# TC37XPD register map
Vendor: Infineon; Series: ATVMC; File version: 100
CPU: other r0p0, little endian, MPU, FPU, vendor SysTick, 4 interrupt priority bits
Registers are 32-bit, read-write, reset 0x0 unless marked. A register's access mark holds for its fields unless they carry their own. Offsets are from the block's base; [hi:lo] are bit positions; {n}, {i} and the like mark numbered series; 'fields as' and 'values as' point back to an identical list.

## SCU (part 2 of 3) — System Control Unit
Base 0xF0036000
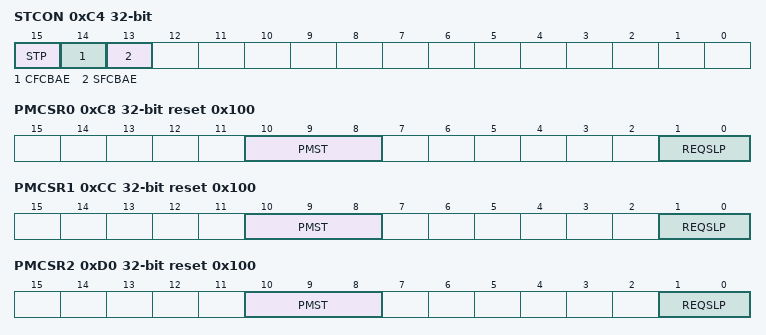
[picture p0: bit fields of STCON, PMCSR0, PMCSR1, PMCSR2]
0xC4 STCON access per field — Start up Configuration Register resetvalue={Application Reset:0x0}
  [15] STP rw — Start up Protection Setting STP. This bit will be always set by FW and can t be reset. This bit is also cleared by an Application Reset. STP is automatically set when a shutdown trap occurs. The start up protection for the system generated out of this bit can be overruled deactivated if bit RTID.RT14 is set AND signal tcu nostp request from the TCU is asserted.
  [14] CFCBAE wo — Clear Flash Config. Sector Access Enable CFCBAE. Setting this bit clears bit STSTAT.FCBAE. Reading this bit returns always a zero.
  [13] SFCBAE wo — Set Flash Config. Sector Access Enable SFCBAE. Setting this bit sets bit STSTAT.FCBAE. Reading this bit returns always a zero. If bits SFCBAE and CFCBAE are both set during the same access then bit STSTAT.FCBAE is set.
0xC8 PMCSR0 access per field reset 0x100 — Power Management Control and Status Register resetvalue={Application Reset:0x100}
  [10:8] PMST ro — Power management Status PMST. This bit field reflects the current status of the CPU.
  [1:0] REQSLP rw — Idle Mode and Sleep Mode Request REQSLP. In Idle Mode or Sleep Mode these bits are cleared in response to an interrupt for the CPU or when bit 15 of the corresponding CPU Watchdog Timer register bit WDTCPUxSR.TIM 15 changes from 0 to 1. In Standby Mode these bits are cleared on wake up. REQSLP maybe written only when either CPU or Safety ENDINIT bits are set to 0. CPU ENDINIT bit has to be set back after REQSLP is written for the mode transition to take place. In case of Safety ENDINIT the mode transition will be issued immediately and does not wait till Safety ENDINIT is set back to 1 again. No explicit acknowledge to SCU on System Standby request. System Standby entry in a few cycles.
0xCC PMCSR1 access per field reset 0x100 — Power Management Control and Status Register resetvalue={Application Reset:0x100}
  fields as PMCSR0
0xD0 PMCSR2 access per field reset 0x100 — Power Management Control and Status Register resetvalue={Application Reset:0x100}
  fields as PMCSR0
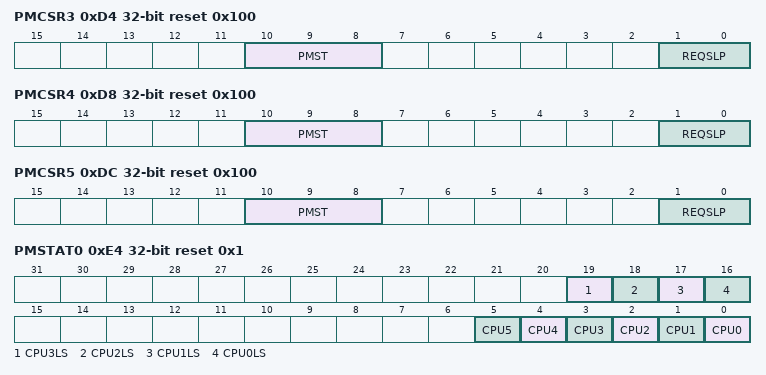
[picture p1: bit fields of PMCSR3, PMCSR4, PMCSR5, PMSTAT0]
0xD4 PMCSR3 access per field reset 0x100 — Power Management Control and Status Register resetvalue={Application Reset:0x100}
  fields as PMCSR0
0xD8 PMCSR4 access per field reset 0x100 — Power Management Control and Status Register resetvalue={Application Reset:0x100}
  fields as PMCSR0
0xDC PMCSR5 access per field reset 0x100 — Power Management Control and Status Register resetvalue={Application Reset:0x100}
  fields as PMCSR0
0xE4 PMSTAT0 ro reset 0x1 — Power Management Status Register 0 resetvalue={Application Reset:0x1}
  [19] CPU3LS — CPU3LS Status CPU3LS. This bit field reflects the current status of CPU3 Lockstep Checker Core.The activation of the Lockstep is configured in UCB BMI configuration and determines the default status. The default reset value 0 is for the case where CPU0LS is disabled in UCB BMI configuration.
  [18] CPU2LS — CPU2LS Status CPU2LS. This bit field reflects the current status of CPU2 Lockstep Checker Core.The activation of the Lockstep is configured in UCB BMI configuration and determines the default status. The default reset value 0 is for the case where CPU0LS is disabled in UCB BMI configuration.
  [17] CPU1LS — CPU1LS Status CPU1LS. This bit field reflects the current status of CPU1 Lockstep Checker Core.The activation of the Lockstep is configured in UCB BMI configuration and determines the default status. The default reset value 0 is for the case where CPU0LS is disabled in UCB BMI configuration.
  [16] CPU0LS — CPU0LS Status CPU0LS. This bit field reflects the current status of CPU0 Lockstep Checker Core.The activation of the Lockstep is configured in UCB BMI configuration and determines the default reset value. The default reset value 0 is for the case where CPU0LS is disabled in UCB BMI configuration.
  [n] CPU{n} (n=0..5) — CPU{n} Status CPU{n}. This bit field reflects the current status of CPU{n}.
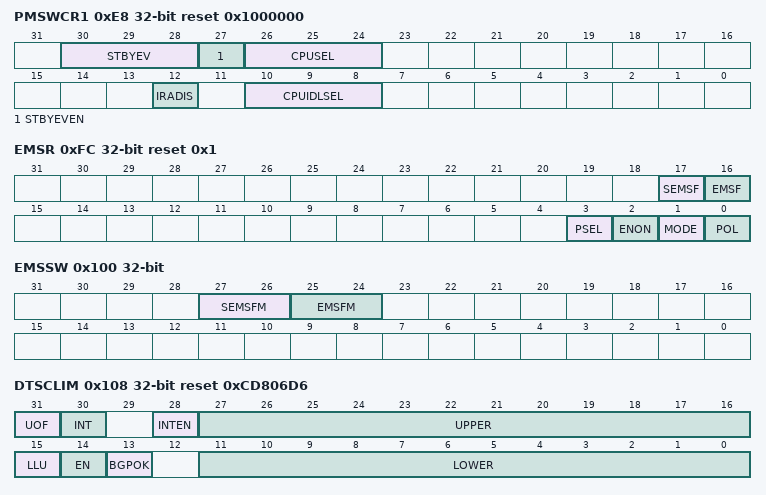
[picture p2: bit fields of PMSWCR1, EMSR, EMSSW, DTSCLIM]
0xE8 PMSWCR1 access per field reset 0x1000000 — Standby and Wake up Control Register 1 resetvalue={Cold PowerOn Reset:0x1000000}
  [30:28] STBYEV rw — Standby Entry Event Configuration STBYEV. All other bit combinations are reserved.
  [27] STBYEVEN wo — Standby Entry Event configuration enable STBYEVEN
  [26:24] CPUSEL rw — CPU selection for Sleep and Standby mode CPUSEL. All other CPUSEL bit combinations are reserved.
  [12] IRADIS rw — Idle Request Acknowledge Sequence Disable IRADIS. This bit enables SCU Idle Request Acknowledge sequence to all modules on Standby entry. IRADIS bit has no effect incase of Standby entry triggered via PWRWKEN register bit. This bit shall be set before Standby entry to disable Idle request acknowledge sequence so that standby request is not blocked by a pending reset idle request acknowledge sequence.
  [10:8] CPUIDLSEL rw — CPU selection for Idle mode CPUIDLSEL. This bit field allows a CPUx to issue Idle request to other CPUs in addition to itself. A request for Idle via PMCSRx.REQSLP 01 by CPUx will also trigger Idle requests to all other CPUs. All other CPUIDLSEL bit combinations are reserved.
0xFC EMSR access per field reset 0x1 — Emergency Stop Register resetvalue={Application Reset:0x1}
  [17] SEMSF ro — SMU Emergency Stop Flag SEMSF. This bit indicates that an SMU Safety Alarm triggered emergency stop condition has occurred.
  [16] EMSF ro — Emergency Stop Flag EMSF. This bit indicates that a synchronous mode port triggered emergency stop condition has occurred.
  [3] PSEL rw — PORT Select PSEL. This bit selects which one of the two Emergency Stop port options is monitored.
  [2] ENON rw — Enable ON ENON. This bit enables the setting of flag EMSF by an inactive to active level transition of input signal.
  [1] MODE rw — Mode Selection MODE. This bit determines the operating mode of the emergency stop signal.
  [0] POL rw — Input Polarity POL. This bit determines the polarity of the configured Emergency Stop input.
0x100 EMSSW wo — Emergency Stop Software set and clear register resetvalue={Application Reset:0x0}
  [27:26] SEMSFM — SMU Emergency Stop Flag Modification SEMSFM. This bit field sets or clears flag SEMSF via software. In case of a simultaneous hardware and software modification request the hardware operation will be executed. SEMSFM is always read as 00 B .
  [25:24] EMSFM — Emergency Stop Flag Modification EMSFM. This bit field sets or clears flag EMSF via software. In case of a simultaneous hardware and software modification request the hardware operation will be executed. EMSFM is always read as 00 B .
0x104 DTSCSTAT ro — Core Die Temperature Sensor Status Register resetvalue={Application Reset:0x0}
  [11:0] RESULT — Result of the DTSC Measurement RESULT. This bit field shows the result of the DTSC measurement. The value given is directly related to the die temperature and can be evaluated using the following formula. T 176 C RESULT Gnom 273.15 T 176 K RESULT G nom RESULT G nom T 176 C 273.15 G nom T 176 K G nom 7.505
0x108 DTSCLIM access per field reset 0xCD806D6 — Core Die Temperature Sensor Limit Register resetvalue={Application Reset:0x0CD806D6}
  [31] UOF rw — DTSC Upper Limit Overflow UOF. When this bit is set the related SMU DTSC alarm trigger is generated. This bit has to be written with zero in order to clear it. Writing a one has no effect. This bit is set when a DTSC measurement is finished and the result is exceeding the upper limit i.e. DTSCLIM.UPPER .
  [30] INT rw — DTSC Interrupt status flag. This bit is set when SMU DTSC interrupt is generated when a DTSC measurement is finished. This bit is cleared by writing a zero. Writing a one has no effect.
  [28] INTEN rw — DTSC Interrupt Enable. This bitfield enables the Core Die Temperature Sensor DTSC interrupt. The bitfield is reset on an application reset.
  [27:16] UPPER rw — DTSC Upper Limit UPPER. This bit field defines the upper limit of the DTSC temperature check. The DTSC measurement result is compared against this value and if the measurement result is greater than or equal to the configured UPPER bitfield value flag UOF is set.
  [15] LLU rw — DTSC Lower Limit Underflow LLU. When this bit is set the related SMU DTSC alarm trigger is generated. This bit has to be written with zero in order to clear it. Writing a one has no effect. This bit is set when a DTSC measurement is finished and the result is below the lower limit i.e. DTSCLIM.LOWER .
  [14] EN rw — DTSC Enable. This bitfield enables the Core Die Temperature Sensor DTSC . The bitfield is reset on an application reset.
  [13] BGPOK ro — DTSC Bandgap OK. This bitfield indicates that the bandgap reference for the Core Die Temperature Sensor DTSC is available and ok.
  [11:0] LOWER rw — DTSC Lower Limit LOWER. This bit field defines the lower limit of the DTSC temperature check. The DTSC measurement result is compared against this value and if the measurement result is less than or equal to the configured LOWER bitfield value flag LLU is set.
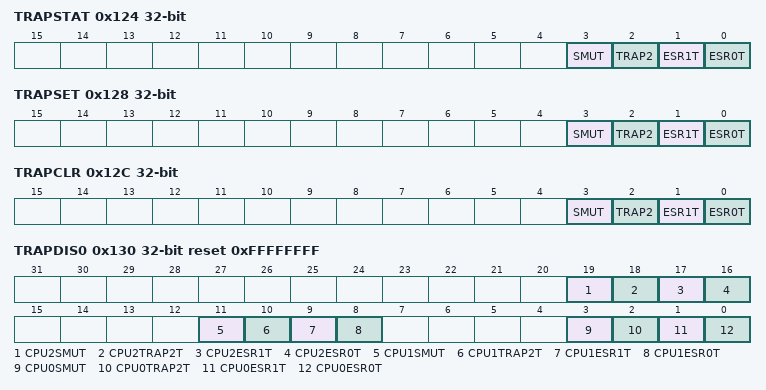
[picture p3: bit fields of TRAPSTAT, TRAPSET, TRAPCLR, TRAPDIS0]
0x124 TRAPSTAT ro (reset mask 0xFFFFFFF0) — Trap Status Register resetvalue={System Reset:0x0}
  [3] SMUT — SMU Alarm Trap Request Flag SMUT. This bit is set if an SMU Alarm is indicated. This bit can be cleared by setting bit TRAPCLR.SMUT. This bit can be set by setting bit TRAPSET.SMUT. Reset value of this bit is 0
  [2] TRAP2 — Trap Bit 2 Request Flag TRAP2. This bit can be cleared by setting bit TRAPCLR.TRAP2. This bit can be set by setting bit TRAPSET.TRAP2. Reset value of this bit is 0
  [1] ESR1T — ESR1 Trap Request Flag ESR1T. This bit is set if an ESR1 event is triggered. This bit can be cleared by setting bit TRAPCLR.ESR1T. This bit can be set by setting bit TRAPSET.ESR1T. Reset value of this bit is 0
  [0] ESR0T — ESR0 Trap Request Flag ESR0T. This bit is set if an ESR0 event is triggered. This bit can be cleared by setting bit TRAPCLR.ESR0T. This bit can be set by setting bit TRAPSET.ESR0T. Observed reset value after boot will depend upon ARI mode because of ESR pin transition.
0x128 TRAPSET wo — Trap Set Register resetvalue={System Reset:0x0}
  [3] SMUT — Set Trap Request Flag SMUT SMUT. Setting this bit sets bit TRAPSTAT.SMUT. Clearing this bit has no effect. Reading this bit returns always zero.
  [2] TRAP2 — Set Trap Request Flag TRAP2 TRAP2. Setting this bit sets bit TRAPSTAT.TRAP2. Clearing this bit has no effect. Reading this bit returns always zero.
  [1] ESR1T — Set Trap Request Flag ESR1T ESR1T. Setting this bit sets bit TRAPSTAT.ESR1T. Clearing this bit has no effect. Reading this bit returns always zero.
  [0] ESR0T — Set Trap Request Flag ESR0T ESR0T. Setting this bit sets bit TRAPSTAT.ESR0T. Clearing this bit has no effect. Reading this bit returns always zero.
0x12C TRAPCLR wo — Trap Clear Register resetvalue={System Reset:0x0}
  [3] SMUT — Clear Trap Request Flag SMUT SMUT. Setting this bit clears bit TRAPSTAT.SMUT. Clearing this bit has no effect. Reading this bit returns always zero.
  [2] TRAP2 — Clear Trap Request Flag TRAP2 TRAP2. Setting this bit clears bit TRAPSTAT.TRAP2. Clearing this bit has no effect. Reading this bit returns always zero.
  [1] ESR1T — Clear Trap Request Flag ESR1T ESR1T. Setting this bit clears bit TRAPSTAT.ESR1T. Clearing this bit has no effect. Reading this bit returns always zero.
  [0] ESR0T — Clear Trap Request Flag ESR0T ESR0T. Setting this bit clears bit TRAPSTAT.ESR0T. Clearing this bit has no effect. Reading this bit returns always zero.
0x130 TRAPDIS0 reset 0xFFFFFFFF — Trap Disable Register 0 resetvalue={Application Reset:0x0FFFFFFFF}
  [19] CPU2SMUT — Disable Trap Request SMUT on CPU2 If product has CPU2 CPU2SMUT
  [18] CPU2TRAP2T — Disable Trap Request TRAP2T on CPU2 If product has CPU2 CPU2TRAP2T
  [17] CPU2ESR1T — Disable Trap Request ESR1T on CPU2 If product has CPU2 CPU2ESR1T
  [16] CPU2ESR0T — Disable Trap Request ESR0T on CPU2 If product has CPU2 CPU2ESR0T
  [11] CPU1SMUT — Disable Trap Request SMUT on CPU1 If product has CPU1 CPU1SMUT
  [10] CPU1TRAP2T — Disable Trap Request TRAP2T on CPU1 If product has CPU1 CPU1TRAP2T
  [9] CPU1ESR1T — Disable Trap Request ESR1T on CPU1 If product has CPU1 CPU1ESR1T
  [8] CPU1ESR0T — Disable Trap Request ESR0T on CPU1 If product has CPU1 CPU1ESR0T
  [3] CPU0SMUT — Disable Trap Request SMUT on CPU0 CPU0SMUT
  [2] CPU0TRAP2T — Disable Trap Request TRAP2T on CPU0 CPU0TRAP2T
  [1] CPU0ESR1T — Disable Trap Request ESR1T on CPU0 CPU0ESR1T
  [0] CPU0ESR0T — Disable Trap Request ESR0T on CPU0 CPU0ESR0T
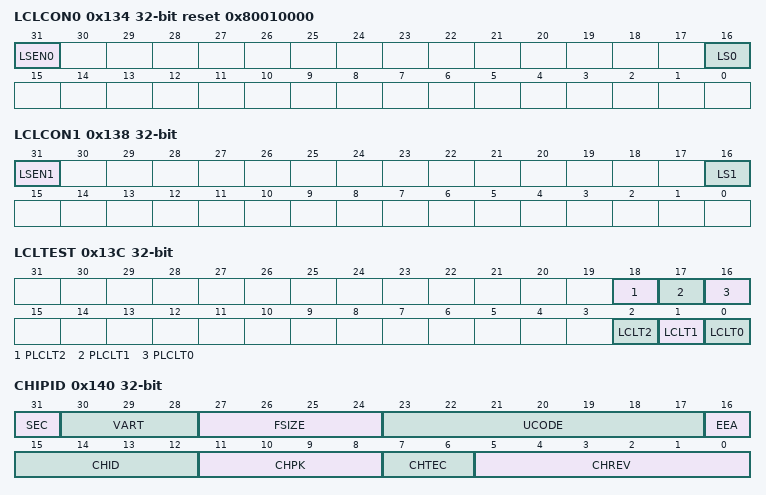
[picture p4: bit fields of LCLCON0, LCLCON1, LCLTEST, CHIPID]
0x134 LCLCON0 access per field reset 0x80010000 — LCL CPU0 and CPU2 Control Register resetvalue={Cold PowerOn Reset:0x080018001,Cold PowerOn Reset:0x080010000,Cold PowerOn Reset:0x080018001}
  [31] LSEN0 rw — Lockstep Enable LSEN0. This bit may only be written by SSW during boot. Enable lockstep CPU monitoring for the associated processor core CPU0. After cold reset lockstep is enabled by default. The LSEN bit may be cleared during the boot to disable lockstep mode. SMU lockstep fault reporting should be disabled when lockstep is disabled.
  [16] LS0 ro — Lockstep Mode Status LS0. This bit indicates whether CPU0 is currently running in lockstep monitor mode
0x138 LCLCON1 access per field (reset mask 0x7FFE7FFE) — LCL CPU1 and CPU3 Control Register resetvalue={Cold PowerOn Reset:0x080018001,Cold PowerOn Reset:0x080010000,Cold PowerOn Reset:0x0,Cold PowerOn Reset:0x080018001}
  [31] LSEN1 rw — Lockstep Enable LSEN1. This bit may only be written by SSW during boot. Enable lockstep CPU monitoring for the associated processor core CPU1. If the product has no lockstep capability for CPU1 then this enables only the PFLASH access monitoring for CPU1. After cold reset lockstep is enabled by default. The LSEN bit may be cleared during the boot to disable lockstep mode. SMU lockstep fault reporting should be disabled when lockstep is disabled.
  [16] LS1 ro — Lockstep Mode Status LS1. This bit indicates whether CPU1 is currently running in lockstep monitor mode
0x13C LCLTEST wo — LCL Test Register resetvalue={System Reset:0x0}
  [18] PLCLT2 — PFI2 Lockstep Test . Fault injection for PFI2 lockstep. Reads as zero.
  [17] PLCLT1 — PFI1 Lockstep Test . Fault injection for PFI1 lockstep. Reads as zero.
  [16] PLCLT0 — PFI0 Lockstep Test. Fault injection for PFI0 lockstep. Reads as zero.
  [2] LCLT2 — LCL2 Lockstep Test LCLT2. Fault injection for LCL2. Reads as zero.
  [1] LCLT1 — LCL1 Lockstep Test LCLT1. Fault injection for LCL1. Reads as zero.
  [0] LCLT0 — LCL0 Lockstep Test LCLT0. Fault injection for LCL0. Reads as zero.
0x140 CHIPID access per field reset not defined — Chip Identification Register resetvalue={System Reset:0x0,CFS Value:0x0}
  [31] SEC rw — Security Device Available SEC. This bit field is updated by SSW from config sector. This bit field indicates whether the product has a Hardware Security Module
  [30:28] VART rw — Variant VART. This bit field is used for variant identification. It is used to identify product variants with non standard temperature profile max frequency package pitch or customer feature sets. Note that variants do not include HSM availability Flash Size or Emulation availability options which are handled by the SEC FSIZE and EEA fields respectively. For coding details see Product Datasheet
  [27:24] FSIZE rw — Program Flash Size FSIZE. This bit field indicates available program flash size for this device. For more details see Product Datasheet.
  [23:17] UCODE rw — µCode Version UCODE. This bit field displays the Version X.Y of the flash µCode.
  [16] EEA ro — Emulation or ADAS Extension Available EEA. Indicates if the emulation or ADAS extension hardware is available or not.
  [15:12] CHID rw — Chip Product CHID. These bits indicate the base product. For further details refer to the Product Datasheet Updated by SSW from config sector.
  [11:8] CHPK rw — Chip Package CHPK. These bits indicate the package. For further details refer to the Product Datasheet Updated by SSW from config sector. Use future variant codes for downconfigured silicon
  [7:6] CHTEC ro — Chip Family CHTEC. These bits indicate the product family and are changed only with a redesign. Hard wired on top level.
  [5:0] CHREV ro — Chip Revision Number CHREV. This bit field indicates the revision number of the AurixPlus Platform device. The value of this bit field is defined in the product Data Sheet. Bits 3 0 are connected to the layer prog inputs 3 0 . Bits 3 0 are used to indicate the steps. These updates can be done with any metal fix or FW ROM change. Bits 5 4 are hard wired on top level. Bits 5 4 define the major silicon design steps A B C D ... . These bits can be changed only with a major redesign.
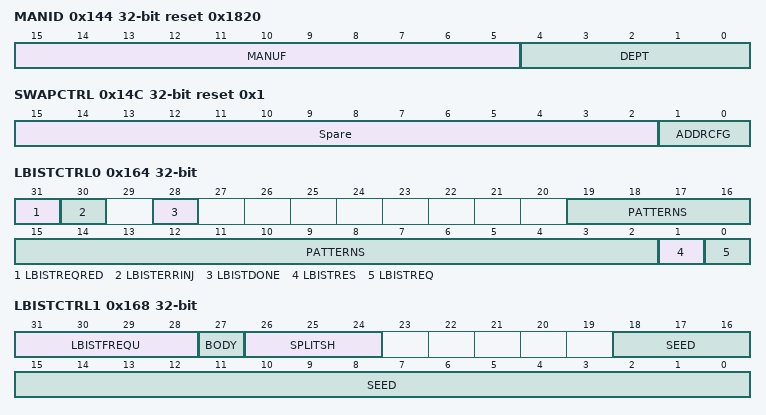
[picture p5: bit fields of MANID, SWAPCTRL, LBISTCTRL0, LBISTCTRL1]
0x144 MANID ro reset 0x1820 — Manufacturer Identification Register resetvalue={System Reset:0x1820}
  [15:5] MANUF — Manufacturer Identification Number MANUF. This is a JEDEC normalized manufacturer code. MANUF C1 H stands for Infineon Technologies.
  [4:0] DEPT — Department Identification Number DEPT. 00 H indicates the Automotive amp Industrial microcontroller department within Infineon Technologies.
0x14C SWAPCTRL reset 0x1 — Address Map Control Register resetvalue={System Reset:0x1}
  [15:2] Spare — Spare address configuration registers. Spare read write bits
  [1:0] ADDRCFG — Address Configuration. Configures the currently used address map standard alternate selection
0x164 LBISTCTRL0 access per field (reset mask 0xEFF00003) — Logic BIST Control 0 Register resetvalue={System Reset:0x0,CFS Value:0x400}
  [31] LBISTREQRED rw — LBIST Request Redundancy. This bit represents the safety double of LBISTCTRL0.LBISTREQ. In order to generate a new LBIST request both LBISTREQRED and LBISTREQ bits must be set to high due to safety reasons. The request will only be approved if LBISTCTRL0.LBISTDONE bit reflects a 0 value. If read this bit always returns a 0 .
  [30] LBISTERRINJ rw — LBIST Test Mode Alarm Error Injection. If written high this bit trigger both the LBIST and the test mode alarm. This is required to allow self testing of all LBIST and test mode related safety mechanisms in the TCU. The bit will be reset automatically once the LBIST and test mode alarm indicator signals from TCU are asserted. From these indicator signals SCU will also generate corresponding alarm trigger signals for SMU.
  [28] LBISTDONE ro — LBIST Execution Indicator LBISTDONE. This bit indicates the actual LBIST controller execution status
  [19:2] PATTERNS rw — LBIST Pattern Number PATTERNS. This field defines the number of scan patterns i.e. scan loads which will be executed during the LBIST procedure. Please note that the value programmed to this field determines the number scan capture phases not the number of scan chain load unload phases i.e. a value of 0x00001 will result in two scan chain loads with on capture in between a value of 0x00002 will result in 3 scan chain loads with 2 captures etc. . Consequently a value of 0x00000 is not valid because no capture would be executed in this case.
  [1] LBISTRES wo — LBIST Reset LBISTRES. If written high this bit synchronously brings back the LBIST controller to its initial Reset Idle state and also clears the stored MISR signature to allow another execution from CPU side. As a consequence the LBISTCTRL0 .LBISTDONE and SCU LBISTCTRL3.SIGNATURE bits will be set to x2019 0 x2019 . If read this bit always returns a x2018 0 x2019 . It is strongly recommended to not change the LBISTFREQU parameter in LBISTCTRL1 after this bit has been set to 1 because there is no guarantee that the new frequency parameter value will be transferred to the LBIST controller in time before the next LBIST run is started from user side i.e. LBISTCTRL0.LBISTREQ is set to 1 .
  [0] LBISTREQ wo — LBIST Request LBISTREQ. If written high this bit requests the execution of an automatic scan test procedure. The request will only be approved if LBISTCTRL0 .LBISTDONE bit reflects a 8217 0 8217 value i.e. no LBIST procedure was triggered since the last power on reset or LBIST controller has been restarted through the LBISTCTRL0 .LBISTRES bit . If read this bit always returns a 8216 0 8217 . This bit shall be implemented in a safety relevant way to avoid unintended activation of LBIST during application. LBIST execution time depends on the number of scan loads as defined in the PATTERNS field.
0x168 LBISTCTRL1 (reset mask 0xABFFFFF8) — Logic BIST Control 1 Register resetvalue={System Reset:0x0,CFS Value:0x54000007}
  [31:28] LBISTFREQU — LBIST Frequency Selection LBISTFREQU. Through this register field a pre scaler factor between 1..16 is selectable for LBIST operation clock derived from EVR oscillator . This will allow to determine the LBIST scan shift frequency. Value of these bits will be mirrored inside of LBIST controller and become effective if a new LBIST procedure has been successfully initiated from system side via LBISTCTRL0 .LBISTREQ . It is strongly recommended not to change the value of this field after LBISTCTRL0.LBISTRES has been set to high because there is no guarantee that the new frequency parameter value will be transferred to the LBIST controller in time before the next LBIST run is started from user side i.e. LBISTCTRL0.LBISTREQ is set to 1
  [27] BODY — Body Application Indicator BODY. The value of this bit will determine the static reset behavior of all GPIOs during LBIST execution. If set to low GPIOs will show a weak pull up behavior if set to high GPIOs are constrained to tri state. A high value must be written to this bit in case LBIST shall be executed for body applications.
  [26:24] SPLITSH — LBIST Split Shift Selection SPLITSH. The value of this bit will allow to run LBIST with partitioned scan shift operation in order to reduce the power consumption.
  [18:0] SEED — LBIST Seed SEED. This field determines which pattern is applied to the EDT channel inputs 1 19 during LBIST execution.
0x16C LBISTCTRL2 (reset mask 0xFFFFFFC2) — Logic BIST Control 2 Register resetvalue={System Reset:0x0,CFS Value:0x3D}
  [11:0] LENGTH — LBIST Maximum Scan Chain Length LENGTH. This field defines the number of shift cycles for each LBIST scan load. It will be automatically loaded with the product specific value stored in Flash config sector during startup software execution.
0x170 LBISTCTRL3 ro — Logic BIST Control 3 Register resetvalue={System Reset:0x0,CFS Value:0x0}
  [31:0] SIGNATURE — LBIST Signature SIGNATURE. This field reflects the MISR signature from the last LBIST execution. It is mirrored from LBIST controller inside TCU and only valid if LBISTCTRL0 .LBISTDONE is read with a high value. In case of a restart of the LBIST controller via LBISTCTRL0 .LBISTRES function the signature value will be synchronously reset to all 0. Please address the specific device appendix document for a description on the SIGNATURE value depending on the LBIST run configuration.
0x184 STMEM1 — Start up Memory Register 1 resetvalue={PowerOn Reset:0x0}
  [31:0] MEM — Memory MEM. This register is used by the start up software as memory.
0x188 STMEM2 — Start up Memory Register 2 resetvalue={System Reset:0x0}
  fields as STMEM1
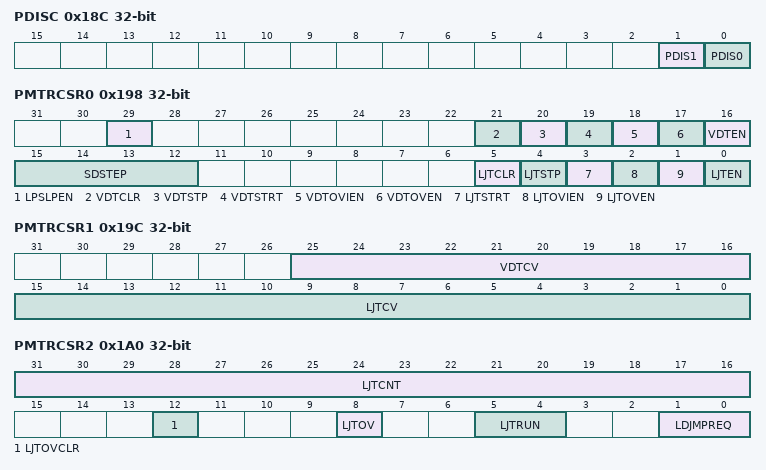
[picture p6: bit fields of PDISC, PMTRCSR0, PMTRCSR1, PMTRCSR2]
0x18C PDISC — Pad Disable Control Register resetvalue={System Reset:0x0}
  [1] PDIS1 — Pad Disable for ESR Pin 1 PDIS1. This bit disables the pad.
  [0] PDIS0 — Pad Disable for ESR Pin 1 PDIS1. This bit disables the pad.
0x198 PMTRCSR0 access per field — Power Management Transition Control and Status Register 0 resetvalue={Cold PowerOn Reset:0x0}
  [29] LPSLPEN rw — EVRC Low Power Mode activation on a Sleep Request LPSLPEN. PMS This bit field enables the activation of LPM EVRC mode on a sleep request. If this bit is set SCU sends lp enable signal on Sleep request to PMS which is OR ed with EVRSDCTRL2.EVRCMOD value and is provided to EVRC regulator. PMSLE Reserved no function no LPM for SC DCDC EVRC .
  [21] VDTCLR wo — Voltage Droop Timer Clear VDTCLR. This bit field clear Voltage Droop timer count. This is intended for test purposes. This bit resets VDT and clears VDTRUN if VDTEN bit is set.
  [20] VDTSTP rw — Voltage Droop Timer Stop VDTSTP. This bit field stops Voltage Droop timer. SCU cancels the droop request via signal sd droop cntr i 160 160 00. This is intended for test purposes. The VDTSTP remains set on a write and is to be explicitly cleared by software. The VDTSTP stops the counter at the current value and timer re starts from that value when VDTSTP is cleared and VDTSTRT is set.
  [19] VDTSTRT rw — Voltage Droop Timer Start VDTSTRT. This bit field starts Voltage Droop timer. This is intended for test purposes. The VDTSTRT remains set on a write and is cleared when VDTOV bit is set if VDTOVEN bit is enabled.
  [18] VDTOVIEN rw — Voltage Droop Timer Overflow Interrupt Enable VDTOVIEN. This bit field enables the activation of interrupt on timer overflow or time out.
  [17] VDTOVEN rw — Voltage Droop Timer Overflow Enable VDTOVEN. This bit field enables the update of VDTOV status bit on timer overflow or time out.
  [16] VDTEN rw — Voltage Droop Timer Enable VDTEN. This bit field enables the usage of Voltage Droop timer.
  [15:12] SDSTEP rw — Droop Voltage Step vdroop step i SDSTEP. This bit field defines the voltage offset for droop compensation on a load jump to the EVRC setpoint value. The request is made via SCU PMTRCSR3 .VDROOPREQ sd droop cntr i on an anticipated load jump with a voltage offset equal to the SDSTEP x 5 160 mV. The droop step is a positive offset if VDROOPREQ 160 160 01b and is a negative offset if VDROOPREQ 160 160 10b and no offset is applied if VDROOPREQ 160 160 00b. Maximum Droop 80 160 mV.
  [5] LJTCLR wo — Load Jump Timer Clear LJTCLR. This bit field clear Load jump timer count. This is intended for test purposes. This bit resets LJT and clears LJTRUN if LJTEN bit is set.
  [4] LJTSTP rw — Load Jump Timer Stop LJTSTP. This bit field stops Load jump timer. This is intended for test purposes. The LJTSTP remains set on a write and is to be explicitly cleared by software. The LJTSTP stops the counter at the current value and timer re starts from that value when LJTSTP is cleared and LJTSTRT is set.
  [3] LJTSTRT rw — Load Jump Timer Start LJTSTRT. This bit field starts Load jump timer. This is intended for test purposes. The LJTSTRT remains set on a write and is cleared when LJTOV bit is set if LJTOVEN bit is enabled.
  [2] LJTOVIEN rw — Load Jump Timer Overflow Interrupt Enable LJTOVIEN. This bit field enables the activation of interrupt on timer overflow or time out.
  [1] LJTOVEN rw — Load Jump Timer Overflow Enable LJTOVEN. This bit field enables the update of LJTOV status bit on timer overflow or time out.
  [0] LJTEN rw — Load Jump Timer Enable LJTEN. This bit field enables the usage of load jump timer.
0x19C PMTRCSR1 — Power Management Transition Control and Status Register 1 resetvalue={Cold PowerOn Reset:0x0}
  [25:16] VDTCV — Voltage Droop Timer Compare Setpoint Value VDTCV. This bit field defines the compare setpoint value of Voltage Droop timer. The compare event would lead to VDTOV bit being set and VDT interrupt being raised. The VDTRUN status bit VDROOPREQ bit and VDTCNT value is reset to 0 on a compare event. 160 160 X 160 us is the compare value. LSB 160 1 160 us. Total range 160 160 1023 160 us
  [15:0] LJTCV — Load Jump Timer Compare Setpoint Value LJTCV. This bit field defines the compare setpoint value of Load Jump timer. The compare event would lead to LJTOV bit being set and LJT interrupt being raised. The LJTRUN status bit LDJMPREQ bit and LJTCNT value is reset to 0 on a compare event. 160 160 X 160 us is the compare value. LSB 160 1 160 us. Total range 160 160 65.5 160 ms
0x1A0 PMTRCSR2 access per field — Power Management Transition Control and Status Register 2 resetvalue={Cold PowerOn Reset:0x0}
  [31:16] LJTCNT ro — Load Jump Timer Value LJTCNT. This bit field reflects the current Load Jump timer value. LJTCNT value is cleared on timer overflow and on a taken Load Jump Request X us is the compare value. LSB 1 us. Total range 65.5 ms
  [12] LJTOVCLR wo — Load Jump Timer Overflow Status Clear LJTOVCLR. This bit clears LJTOV status bit and sets VDROOPREQ and LDJMPREQ to 0 if LJTOVEN bit is enabled. This bit always reads as 0.
  [8] LJTOV ro — Load Jump Timer Overflow Status LJTOV. This status bit indicates that the Load Jump timer compare match has happened. if LJTOVEN bit is enabled then LJTOV can only be cleared explicitly via LJTOVCLR bit. if LJTOVEN bit is disabled LJTOV is cleared on a taken Load Jump Request A new Load Jump request is taken only if both LJT amp VDT are not currently running and no active Load Jump request is being processed . LJTOV being set will lead to an interrupt if LJTOVIEN is enabled.
  [5:4] LJTRUN ro — Load Jump Timer Run Status LJTRUN. This status bit indicates that the Load Jump timer is currently running and a Load Jump is currently taking place. The LJTRUN bit is cleared on a compare overflow. All other bit combinations are reserved.
  [1:0] LDJMPREQ rw — Load Jump Request LDJMPREQ. This bit requests a Load Jump consequently leading to Load Jump Timer start and LJTRUN bit being set if LJTEN 1. The request is not taken if LJTRUN bit is already in set state and LJT is currently running. The request is not taken if VDTRUN bit is already in set state and VDT is currently running. The request is also not taken if LJTOV bit is set AND LJTOVEN bit is enabled . The request is also not taken if VDTOV bit is set AND VDTOVEN bit is enabled . The LDJMPREQ bit is cleared on a compare overflow. All other bit combinations are reserved.
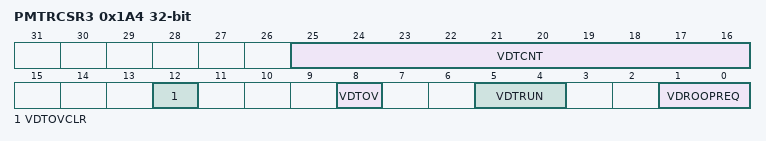
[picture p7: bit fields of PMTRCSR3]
0x1A4 PMTRCSR3 access per field — Power Management Transition Control and Status Register 3 resetvalue={Cold PowerOn Reset:0x0}
  [25:16] VDTCNT ro — Voltage Droop Timer Value VDTCNT. This bit field reflects the current Voltage Droop timer value. VDTCNT value is cleared on timer overflow and on a taken Voltage Droop Request. X us is the compare value. LSB 1 us. Total range 65.5 ms
  [12] VDTOVCLR wo — Voltage Droop Timer Overflow Status Clear VDTOVCLR. This bit clears VDTOV status bit if VDTOVEN bit is enabled. If VDTOVEN bit is disabled this bit has no effect. This bit always reads as 0.
  [8] VDTOV ro — Voltage Droop Timer Overflow Status VDTOV. This status bit indicates that the Voltage Droop timer compare match has happened. if VDTOVEN bit is enabled then VDTOV can only be cleared by explicitly via VDTOVCLR bit. if VDTOVEN bit is disabled VDTOV is cleared on a taken Voltage Droop Request A new Voltage Droop request is taken only if both LJT amp VDT are not currently running and no active Voltage Droop request is being processed . VDTOV being set will lead to an interrupt if VDTOVIEN is enabled. Incase SDVOK is set by EVRC before VDT compare match VDTOV bit is not set.
  [5:4] VDTRUN ro — Voltage Droop Timer Run Status VDTRUN. This status bit indicates that the Voltage Droop timer is currently running and a Voltage Droop is currently taking place. The VDTRUN bit is cleared on a compare overflow. All other bit combinations are reserved.
  [1:0] VDROOPREQ rw — Voltage Droop Request VDROOPREQ. This bit requests a Voltage Droop consequently leading to Voltage Droop Timer start and VDTRUN bit being set if VDTEN 1 . The request is not taken if VDTRUN bit is already in set state and VDT is currently running. The request is also not taken if VDTOV bit is set AND VDTOVEN bit is enabled . The droop step is a positive offset if sd droop cntr i 160 160 01 and is a negative offset if sd droop cntr i 160 160 10 and no offset is applied if sd droop cntr i 160 160 00 and is applied immediately.
